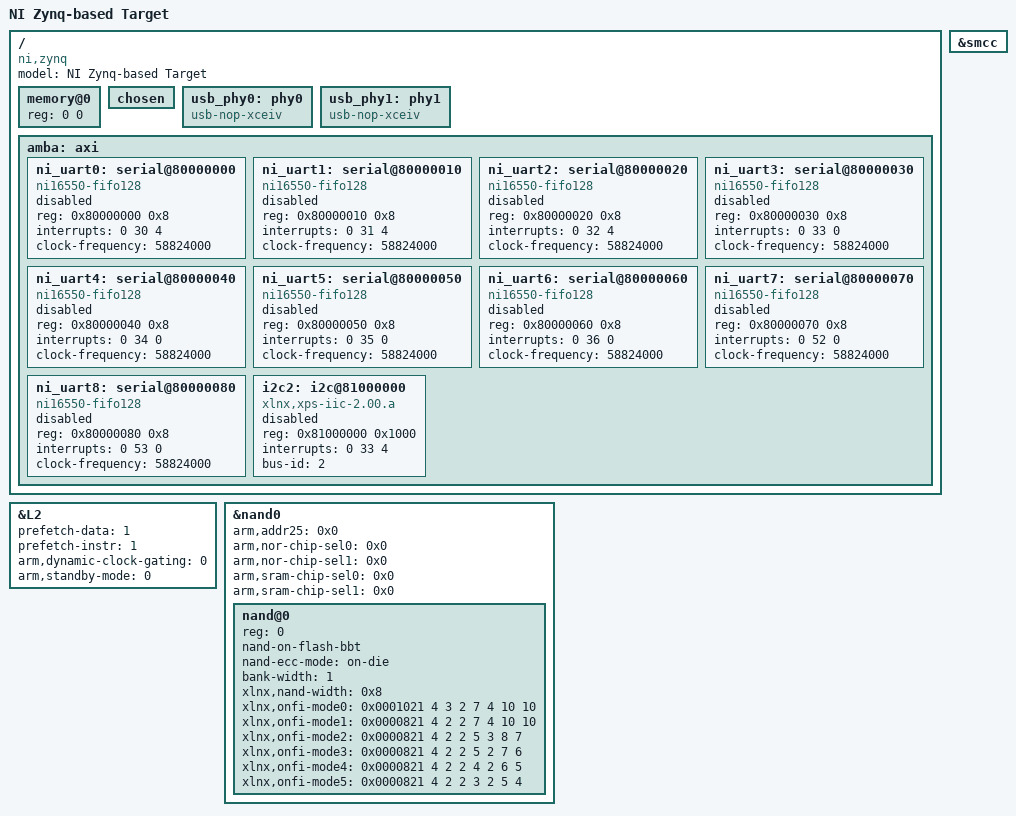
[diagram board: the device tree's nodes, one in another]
/include/ "zynq-7000.dtsi"

/ {
	model = "NI Zynq-based Target";
	compatible = "ni,zynq", "xlnx,zynq-7000";

	/* Populated by the bootloader */
	memory@0 {
		device_type = "memory";
		reg = <0 0>;
	};
	chosen { };

	usb_phy0: phy0 {
		compatible = "usb-nop-xceiv";
		#phy-cells = <0>;
	};

	usb_phy1: phy1 {
		compatible = "usb-nop-xceiv";
		#phy-cells = <0>;
	};

	amba: axi {
		ni_uart0: serial@80000000 {
			device_type = "serial";
			compatible = "ni16550-fifo128", "ns16550a";
			status = "disabled";
			reg = <0x80000000 0x8>;
			interrupts = <0 30 4>;
			clock-frequency = <58824000>;
			/* Populated by the bootloader */
			/* current-speed = <0>; */
		};

		ni_uart1: serial@80000010 {
			device_type = "serial";
			compatible = "ni16550-fifo128", "ns16550a";
			status = "disabled";
			reg = <0x80000010 0x8>;
			interrupts = <0 31 4>;
			clock-frequency = <58824000>;
		};

		ni_uart2: serial@80000020 {
			device_type = "serial";
			compatible = "ni16550-fifo128", "ns16550a";
			status = "disabled";
			reg = <0x80000020 0x8>;
			interrupts = <0 32 4>;
			clock-frequency = <58824000>;
		};

		ni_uart3: serial@80000030 {
			device_type = "serial";
			compatible = "ni16550-fifo128", "ns16550a";
			status = "disabled";
			reg = <0x80000030 0x8>;
			interrupts = <0 33 0>;
			clock-frequency = <58824000>;
		};

		ni_uart4: serial@80000040 {
			device_type = "serial";
			compatible = "ni16550-fifo128", "ns16550a";
			status = "disabled";
			reg = <0x80000040 0x8>;
			interrupts = <0 34 0>;
			clock-frequency = <58824000>;
		};

		ni_uart5: serial@80000050 {
			device_type = "serial";
			compatible = "ni16550-fifo128", "ns16550a";
			status = "disabled";
			reg = <0x80000050 0x8>;
			interrupts = <0 35 0>;
			clock-frequency = <58824000>;
		};

		ni_uart6: serial@80000060 {
			device_type = "serial";
			compatible = "ni16550-fifo128", "ns16550a";
			status = "disabled";
			reg = <0x80000060 0x8>;
			interrupts = <0 36 0>;
			clock-frequency = <58824000>;
		};

		ni_uart7: serial@80000070 {
			device_type = "serial";
			compatible = "ni16550-fifo128", "ns16550a";
			status = "disabled";
			reg = <0x80000070 0x8>;
			interrupts = <0 52 0>;
			clock-frequency = <58824000>;
		};

		ni_uart8: serial@80000080 {
			device_type = "serial";
			compatible = "ni16550-fifo128", "ns16550a";
			status = "disabled";
			reg = <0x80000080 0x8>;
			interrupts = <0 53 0>;
			clock-frequency = <58824000>;
		};


		i2c2: i2c@81000000 {
			compatible = "xlnx,xps-iic-2.00.a";
			status = "disabled";
			reg = <0x81000000 0x1000>;
			interrupts = <0 33 4>;
			bus-id = <2>;
			#address-cells = <1>;
			#size-cells = <0>;
		};
	};

};

&L2 {
	prefetch-data = <1>;
	prefetch-instr = <1>;
	arm,dynamic-clock-gating = <0>;
	arm,standby-mode = <0>;
};

&smcc {
	status = "okay";
};

&nand0 {
	status = "okay";
	arm,addr25 = <0x0>;
	arm,nor-chip-sel0 = <0x0>;
	arm,nor-chip-sel1 = <0x0>;
	arm,sram-chip-sel0 = <0x0>;
	arm,sram-chip-sel1 = <0x0>;

	nand@0 {
		reg = <0>;
		nand-on-flash-bbt;
		nand-ecc-mode = "on-die";
		bank-width = <1>; /* 8-bit width */
		xlnx,nand-width = <0x8>;

		/* SLCR SMC_CLK_CTRL value, 83MHz clock, 12ns cycle time */
		/* <t_rr t_ar t_clr t_wp t_rea t_wc t_rc> in cycles */
		xlnx,onfi-mode0 = <0x0001021 4 3 2 7 4 10 10>;

		/* SLCR SMC_CLK_CTRL value, 166MHz clock, 6ns cycle time */
		/* <t_rr t_ar t_clr t_wp t_rea t_wc t_rc> in cycles */
		xlnx,onfi-mode1 = <0x0000821 4 2 2 7 4 10 10>;
		xlnx,onfi-mode2 = <0x0000821 4 2 2 5 3 8 7>;
		xlnx,onfi-mode3 = <0x0000821 4 2 2 5 2 7 6>;
		xlnx,onfi-mode4 = <0x0000821 4 2 2 4 2 6 5>;
		xlnx,onfi-mode5 = <0x0000821 4 2 2 3 2 5 4>;

		#address-cells = <1>;
		#size-cells = <1>;
	};
};
